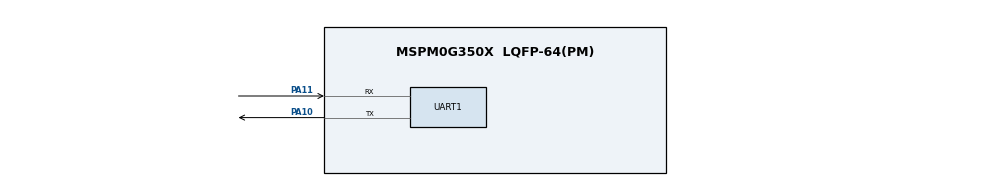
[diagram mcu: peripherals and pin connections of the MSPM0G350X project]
/**
 * @cliArgs --device "MSPM0G350X" --part "Default" --package "LQFP-64(PM)" --product "mspm0_sdk@2.02.00.05"
 * @versions {"tool":"1.21.0+3721"}
 */

/**
 * Import the modules used in this configuration.
 */
const SYSCTL = scripting.addModule("/ti/driverlib/SYSCTL");
const UART   = scripting.addModule("/ti/driverlib/UART", {}, false);
const UART1  = UART.addInstance();

/**
 * Write custom configuration values to the imported modules.
 */
SYSCTL.forceDefaultClkConfig = true;

const Board = scripting.addModule("/ti/driverlib/Board", {}, false);

UART1.$name                    = "UART_0";
UART1.uartClkSrc               = "LFCLK";
UART1.ovsRate                  = "3";
UART1.enableFIFO               = true;
UART1.rxFifoThreshold          = "DL_UART_RX_FIFO_LEVEL_ONE_ENTRY";
UART1.enableDMARX              = false;
UART1.enableDMATX              = false;
UART1.enabledInterrupts        = ["RX"];
UART1.peripheral.$assign       = "UART0";
UART1.peripheral.rxPin.$assign = "PA11";
UART1.peripheral.txPin.$assign = "PA10";
UART1.txPinConfig.$name        = "ti_driverlib_gpio_GPIOPinGeneric0";
UART1.rxPinConfig.$name        = "ti_driverlib_gpio_GPIOPinGeneric1";

/**
 * Pinmux solution for unlocked pins/peripherals. This ensures that minor changes to the automatic solver in a future
 * version of the tool will not impact the pinmux you originally saw.  These lines can be completely deleted in order to
 * re-solve from scratch.
 */
SYSCTL.peripheral.$suggestSolution         = "SYSCTL";
Board.peripheral.$suggestSolution          = "DEBUGSS";
Board.peripheral.swclkPin.$suggestSolution = "PA20";
Board.peripheral.swdioPin.$suggestSolution = "PA19";
